# ESP32-S2 register map
Vendor: ESPRESSIF SYSTEMS (SHANGHAI) CO., LTD.; Series: ESP32 S-Series; File version: 20
CPU: Xtensa LX7 r0p0, little endian, no MPU, no FPU, 0 interrupt priority bits
Address unit: 32 bits
Registers are 32-bit, read-write, reset 0x0 unless marked. A register's access mark holds for its fields unless they carry their own. Offsets are from the block's base; [hi:lo] are bit positions; {n}, {i} and the like mark numbered series.

## BB — BB Peripheral
Base 0x3F41D000
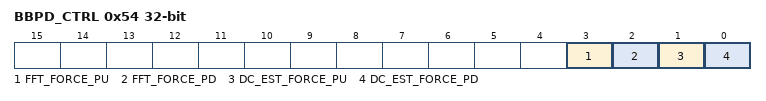
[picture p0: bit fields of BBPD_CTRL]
0x54 BBPD_CTRL — Baseband control register
  [3] FFT_FORCE_PU, [2] FFT_FORCE_PD, [1] DC_EST_FORCE_PU, [0] DC_EST_FORCE_PD

## DEDICATED_GPIO — DEDICATED_GPIO Peripheral
Base 0x3F4CF000
0x00 OUT_DRT wo — Dedicated GPIO directive output register
  [7:0] VALUE — This register is used to configure directive output value of 8-channel dedicated GPIO.
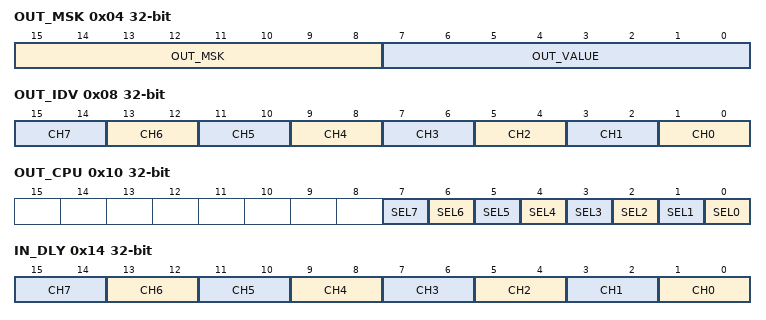
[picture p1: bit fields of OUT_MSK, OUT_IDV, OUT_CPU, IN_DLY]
0x04 OUT_MSK wo — Dedicated GPIO mask output register
  [15:8] OUT_MSK — This register is used to configure channels which would be updated. 1: corresponding channel's output would be updated.
  [7:0] OUT_VALUE — This register is used to configure updated output value of 8-channel dedicated GPIO.
0x08 OUT_IDV wo — Dedicated GPIO individual output register
  [2n+1:2n] CH{n} (n=0..7) — Configure channel {n} output value. 0: hold output value. 1: set output value. 2: clear output value. 3: inverse output value.
0x0C OUT_SCAN ro — Dedicated GPIO output status register
  [7:0] OUT_STATUS — GPIO out value configured by DEDIC_GPIO_OUT_DRT_REG, DEDIC_GPIO_OUT_MSK_REG, DEDIC_GPIO_OUT_IDV_REG.
0x10 OUT_CPU — Dedicated GPIO output mode selection register
  [n] SEL{n} (n=0..7) — Select GPIO out value configured by registers or CPU instructions for channel {n}. 0: Configured by registers. 1: configured by CPU instructions.
0x14 IN_DLY — Dedicated GPIO input delay configuration register
  [2n+1:2n] CH{n} (n=0..7) — Configure GPIO{n} input delay. 0: no delay. 1: one clock delay. 2: two clock delay. 3: three clock delay.
0x18 IN_SCAN ro — Dedicated GPIO input status register
  [7:0] IN_STATUS — GPIO input value after configured by DEDIC_GPIO_IN_DLY_REG.
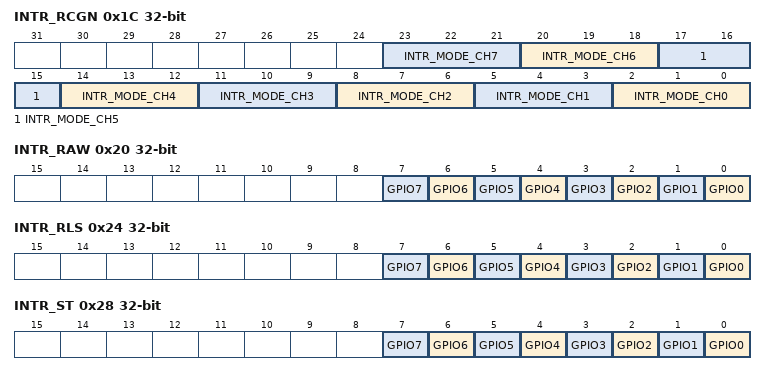
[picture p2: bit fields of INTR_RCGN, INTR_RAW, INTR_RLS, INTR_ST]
0x1C INTR_RCGN — Dedicated GPIO interrupts generation mode register
  [3n+2:3n] INTR_MODE_CH{n} (n=0..7) — Configure channel {n} interrupt generate mode. 0/1: do not generate interrupt. 2: low level trigger. 3: high level trigger. 4: falling edge trigger. 5: raising edge trigger. 6/7: falling and raising edge trigger.
0x20 INTR_RAW ro — Raw interrupt status
  [n] GPIO{n} (n=0..7) — This interrupt raw bit turns to high level when dedicated GPIO{n} has level/edge change configured by DEDIC_GPIO_INTR_RCGN_REG.
0x24 INTR_RLS — Interrupt enable bits
  [n] GPIO{n} (n=0..7) — The enable bit for DEDIC_GPIO{n}_INT_ST register.
0x28 INTR_ST ro — Masked interrupt status
  [n] GPIO{n} (n=0..7) — This is the status bit for DEDIC_GPIO{n}_INT_RAW when DEDIC_GPIO7_INT_ENA is set to 1.
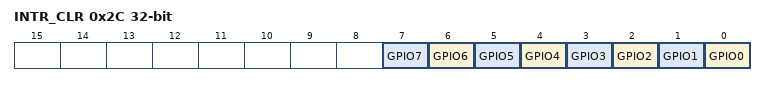
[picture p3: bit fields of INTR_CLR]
0x2C INTR_CLR wo — Interrupt clear bits
  [n] GPIO{n} (n=0..7) — Set this bit to clear the DEDIC_GPIO{n}_INT_RAW interrupt.

## I2C_ANA_MST — I2C Analog Master
Base 0x6000E000
0x00 CONFIG2 — I2C RTC Configuration register 2
  [25] BUSY ro — I2C RTC Busy
  [24] WR_CNTL — I2C RTC Write Control
  [22] BOD_MASK — I2C RTC BOD Mask
  [18] SAR_MASK — I2C RTC SAR Mask
  [23:16] DATA — I2C RTC Data
  [15:8] ADDR — I2C RTC Address
  [7:0] SLAVE_ID — I2C RTC Slave ID
0x44 CONFIG1 — I2C RTC Configuration register 1
  [22] BOD — I2C RTC BOD Mask
  [18] SAR — I2C RTC SAR Mask
  [17] BBPLL — I2C RTC BBPLL Mask
  [14] APLL — I2C RTC APLL Mask
  [22:8] ALL_MASK — I2C RTC All Mask
  [16:4] MAGIC_CTRL — I2C RTC Magic Control
0x48 CONFIG0 — I2C RTC Configuration register 0
  [16:4] MAGIC_CTRL — I2C RTC Magic Control

## DS — Digital Signature
Base 0x6003D000
{0x0+4i} C_MEM[{i}] (i=0..395) access not given — memory C
{0x630+4i} IV_{i} (i=0..3) wo — IV block data.
  [31:0] IV
{0x800+4i} X_MEM[{i}] (i=0..127) access not given — memory X
{0xA00+4i} Z_MEM[{i}] (i=0..127) access not given — memory Z
0xE00 SET_START wo — Activates the DS peripheral
  [0] SET_START — Write 1 to this register to activate the DS peripheral.
0xE04 SET_ME wo — Starts DS operation
  [0] SET_ME — Write 1 to this register to start DS operation.
0xE08 SET_FINISH wo — Ends DS operation
  [0] SET_FINISH — Write 1 to this register to end DS operation.
0xE0C QUERY_BUSY ro — Status of the DS
  [0] QUERY_BUSY — 1: The DS peripheral is busy. 0: The DS peripheral is idle.
0xE10 QUERY_KEY_WRONG ro — Checks the reason why DS_KEY is not ready.
  [3:0] QUERY_KEY_WRONG — 1-15: HMAC was activated, but the DS peripheral did not successfully receive the DS_KEY value from the HMAC peripheral. The biggest value is 15. 0: HMAC is not activated.
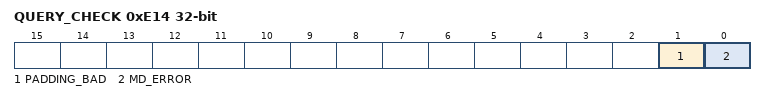
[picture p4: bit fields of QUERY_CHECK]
0xE14 QUERY_CHECK ro — Queries DS check result
  [1] PADDING_BAD — 1: The padding check fails. 0: The padding check passes.
  [0] MD_ERROR — 1: MD check fails. 0: MD check passes.
0xE20 DATE — Version control register

## Notices in the file
Copyright 2025 Espressif Systems (Shanghai) PTE LTD
Licensed under the Apache License, Version 2.0 (the "License");
you may not use this file except in compliance with the License.
You may obtain a copy of the License at
http://www.apache.org/licenses/LICENSE-2.0
Unless required by applicable law or agreed to in writing, software
distributed under the License is distributed on an "AS IS" BASIS,
WITHOUT WARRANTIES OR CONDITIONS OF ANY KIND, either express or implied.
See the License for the specific language governing permissions and
limitations under the License.
